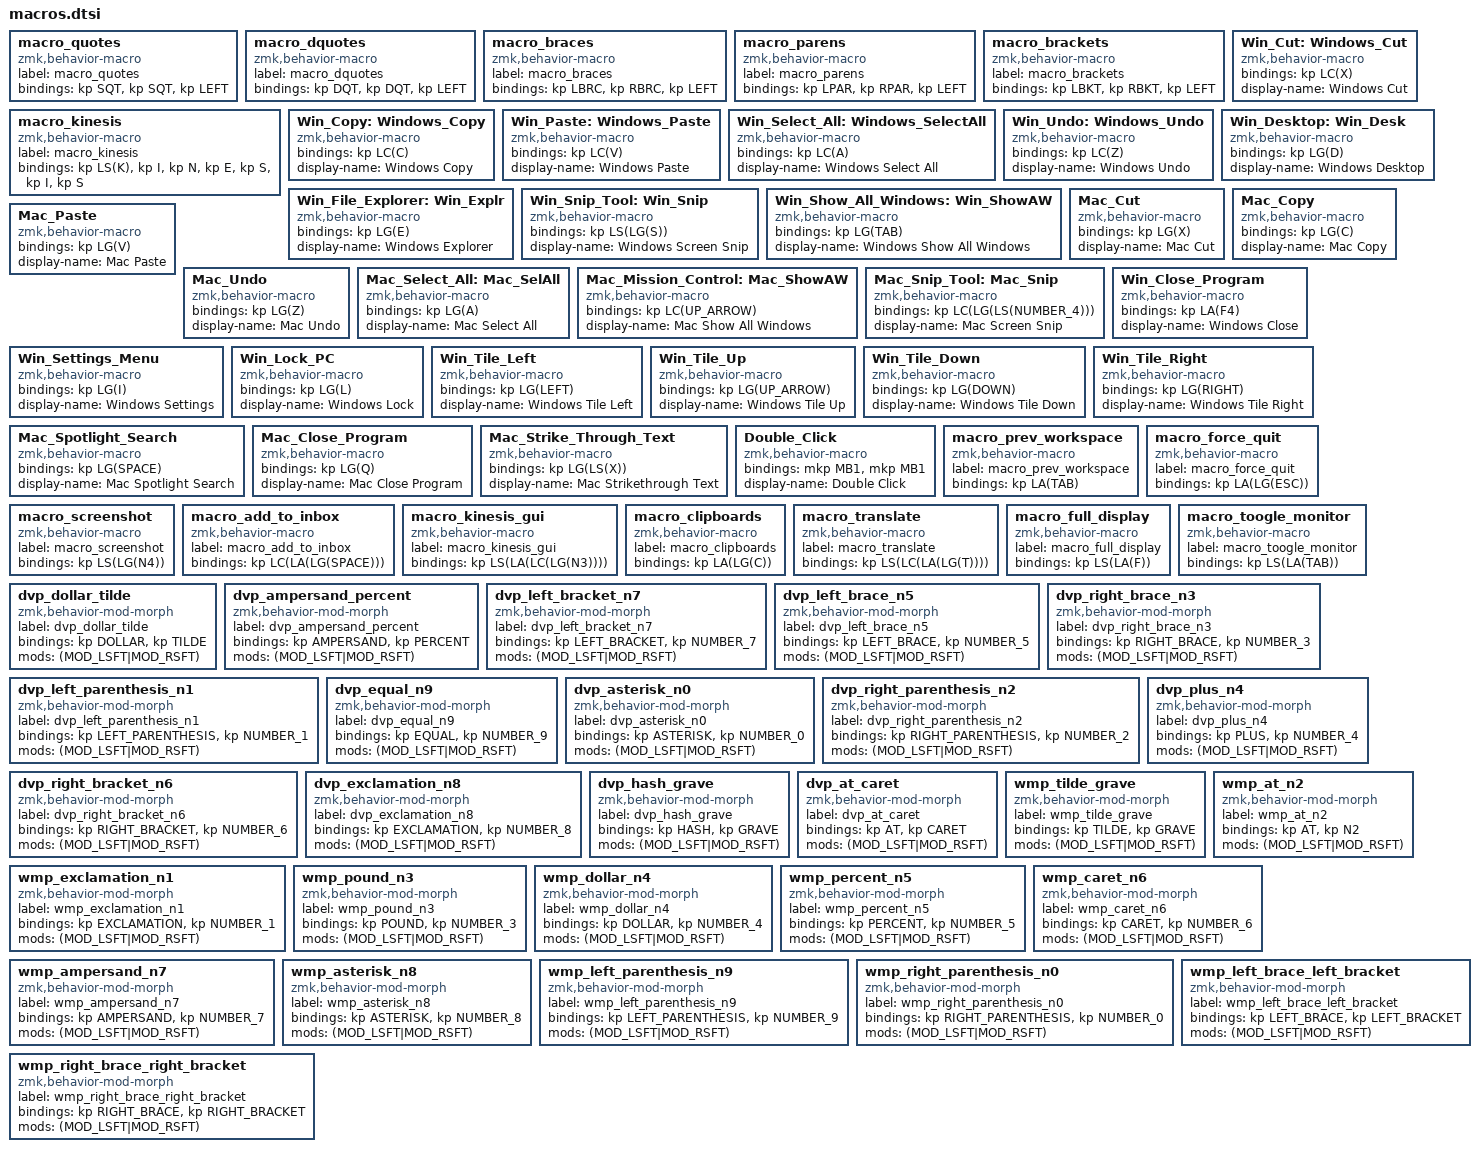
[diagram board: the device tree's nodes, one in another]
macro_quotes: macro_quotes {
    compatible = "zmk,behavior-macro";
    label = "macro_quotes";
    #binding-cells = <0>;
    bindings = <&kp SQT>, <&kp SQT>, <&kp LEFT>;
  };
  macro_dquotes: macro_dquotes {
    compatible = "zmk,behavior-macro";
    label = "macro_dquotes";
    #binding-cells = <0>;
    bindings = <&kp DQT>, <&kp DQT>, <&kp LEFT>;
  };
  macro_braces: macro_braces {
    compatible = "zmk,behavior-macro";
    label = "macro_braces";
    #binding-cells = <0>;
    bindings = <&kp LBRC>, <&kp RBRC>, <&kp LEFT>;
  };
  macro_parens: macro_parens {
    compatible = "zmk,behavior-macro";
    label = "macro_parens";
    #binding-cells = <0>;
    bindings = <&kp LPAR>, <&kp RPAR>, <&kp LEFT>;
  };
  macro_brackets: macro_brackets {
    compatible = "zmk,behavior-macro";
    label = "macro_brackets";
    #binding-cells = <0>;
    bindings = <&kp LBKT>, <&kp RBKT>, <&kp LEFT>;
  };
  macro_kinesis: macro_kinesis {
    compatible = "zmk,behavior-macro";
    label = "macro_kinesis";
    #binding-cells = <0>;
    bindings = <&kp LS(K)>, <&kp I>, <&kp N>, <&kp E>, <&kp S>, <&kp I>, <&kp S>;
  };
  Win_Cut: Windows_Cut {
    compatible = "zmk,behavior-macro";
    #binding-cells = <0>;
    bindings = <&kp LC(X)>;
    display-name = "Windows Cut";
  };

  Win_Copy: Windows_Copy {
    compatible = "zmk,behavior-macro";
    #binding-cells = <0>;
    bindings = <&kp LC(C)>;
    display-name = "Windows Copy";
  };

  Win_Paste: Windows_Paste {
    compatible = "zmk,behavior-macro";
    #binding-cells = <0>;
    bindings = <&kp LC(V)>;
    display-name = "Windows Paste";
  };

  Win_Select_All: Windows_SelectAll {
      compatible = "zmk,behavior-macro";
      #binding-cells = <0>;
      bindings = <&kp LC(A)>;
      display-name = "Windows Select All";
  };

  Win_Undo: Windows_Undo {
    compatible = "zmk,behavior-macro";
    #binding-cells = <0>;
    bindings = <&kp LC(Z)>;
    display-name = "Windows Undo";
  };

  Win_Desktop: Win_Desk {
    compatible = "zmk,behavior-macro";
    #binding-cells = <0>;
    bindings = <&kp LG(D)>;
    display-name = "Windows Desktop";
  };

  Win_File_Explorer: Win_Explr {
    compatible = "zmk,behavior-macro";
    #binding-cells = <0>;
    bindings = <&kp LG(E)>;
    display-name = "Windows Explorer";
  };

  Win_Snip_Tool: Win_Snip {
    compatible = "zmk,behavior-macro";
    #binding-cells = <0>;
    bindings = <&kp LS(LG(S))>;
    display-name = "Windows Screen Snip";
  };

  Win_Show_All_Windows: Win_ShowAW {
    compatible = "zmk,behavior-macro";
    #binding-cells = <0>;
    bindings = <&kp LG(TAB)>;
    display-name = "Windows Show All Windows";
  };

  Mac_Cut: Mac_Cut {
    compatible = "zmk,behavior-macro";
    #binding-cells = <0>;
    bindings = <&kp LG(X)>;
    display-name = "Mac Cut";
  };

  Mac_Copy: Mac_Copy {
    compatible = "zmk,behavior-macro";
    #binding-cells = <0>;
    bindings = <&kp LG(C)>;
    display-name = "Mac Copy";
  };

  Mac_Paste: Mac_Paste {
    compatible = "zmk,behavior-macro";
    #binding-cells = <0>;
    bindings = <&kp LG(V)>;
    display-name = "Mac Paste";
  };

  Mac_Undo: Mac_Undo {
    compatible = "zmk,behavior-macro";
    #binding-cells = <0>;
    bindings = <&kp LG(Z)>;
    display-name = "Mac Undo";
  };

  Mac_Select_All: Mac_SelAll {
    compatible = "zmk,behavior-macro";
    #binding-cells = <0>;
    bindings = <&kp LG(A)>;
    display-name = "Mac Select All";
  };

  Mac_Mission_Control: Mac_ShowAW {
    compatible = "zmk,behavior-macro";
    #binding-cells = <0>;
    bindings = <&kp LC(UP_ARROW)>;
    display-name = "Mac Show All Windows";
  };

  Mac_Snip_Tool: Mac_Snip {
    compatible = "zmk,behavior-macro";
    #binding-cells = <0>;
    bindings = <&kp LC(LG(LS(NUMBER_4)))>;
    display-name = "Mac Screen Snip";
  };

  Win_Close_Program: Win_Close_Program {
    compatible = "zmk,behavior-macro";
    #binding-cells = <0>;
    bindings = <&kp LA(F4)>;
    display-name = "Windows Close";
  };

  Win_Settings_Menu: Win_Settings_Menu {
    compatible = "zmk,behavior-macro";
    #binding-cells = <0>;
    bindings = <&kp LG(I)>;
    display-name = "Windows Settings";
  };

  Win_Lock_PC: Win_Lock_PC {
    compatible = "zmk,behavior-macro";
    #binding-cells = <0>;
    bindings = <&kp LG(L)>;
    display-name = "Windows Lock";
  };

  Win_Tile_Left: Win_Tile_Left {
    compatible = "zmk,behavior-macro";
    #binding-cells = <0>;
    bindings = <&kp LG(LEFT)>;
    display-name = "Windows Tile Left";
  };

  Win_Tile_Up: Win_Tile_Up {
    compatible = "zmk,behavior-macro";
    #binding-cells = <0>;
    bindings = <&kp LG(UP_ARROW)>;
    display-name = "Windows Tile Up";
  };

  Win_Tile_Down: Win_Tile_Down {
    compatible = "zmk,behavior-macro";
    #binding-cells = <0>;
    bindings = <&kp LG(DOWN)>;
    display-name = "Windows Tile Down";
  };

  Win_Tile_Right: Win_Tile_Right {
    compatible = "zmk,behavior-macro";
    #binding-cells = <0>;
    bindings = <&kp LG(RIGHT)>;
    display-name = "Windows Tile Right";
  };

  Mac_Spotlight_Search: Mac_Spotlight_Search {
    compatible = "zmk,behavior-macro";
    #binding-cells = <0>;
    bindings = <&kp LG(SPACE)>;
    display-name = "Mac Spotlight Search";
  };

  Mac_Close_Program: Mac_Close_Program {
    compatible = "zmk,behavior-macro";
    #binding-cells = <0>;
    bindings = <&kp LG(Q)>;
    display-name = "Mac Close Program";
  };

  Mac_Strike_Through_Text: Mac_Strike_Through_Text {
    compatible = "zmk,behavior-macro";
    #binding-cells = <0>;
    bindings = <&kp LG(LS(X))>;
    display-name = "Mac Strikethrough Text";
  };

  Double_Click: Double_Click {
    compatible = "zmk,behavior-macro";
    #binding-cells = <0>;
    bindings = <&mkp MB1 &mkp MB1>;
    display-name = "Double Click";
  };
macro_prev_workspace: macro_prev_workspace{
  compatible = "zmk,behavior-macro";
  label = "macro_prev_workspace";
  #binding-cells = <0>;
  bindings = <&kp LA(TAB)>;
};
macro_force_quit: macro_force_quit{
  compatible = "zmk,behavior-macro";
  label = "macro_force_quit";
  #binding-cells = <0>;
  bindings = <&kp LA(LG(ESC))>;
};
macro_screenshot: macro_screenshot{
  compatible = "zmk,behavior-macro";
  label = "macro_screenshot";
  #binding-cells = <0>;
  bindings = <&kp LS(LG(N4))>;
};
macro_add_to_inbox: macro_add_to_inbox{
  compatible = "zmk,behavior-macro";
  label = "macro_add_to_inbox";
  #binding-cells = <0>;
  bindings = <&kp LC(LA(LG(SPACE)))>;
};
macro_kinesis_gui: macro_kinesis_gui{
  compatible = "zmk,behavior-macro";
  label = "macro_kinesis_gui";
  #binding-cells = <0>;
  bindings = <&kp LS(LA(LC(LG(N3))))>;
};
macro_clipboards: macro_clipboards{
  compatible = "zmk,behavior-macro";
  label = "macro_clipboards";
  #binding-cells = <0>;
  bindings = <&kp LA(LG(C))>;
};
macro_translate: macro_translate{
  compatible = "zmk,behavior-macro";
  label = "macro_translate";
  #binding-cells = <0>;
  bindings = <&kp LS(LC(LA(LG(T))))>;
};
macro_full_display: macro_full_display{
  compatible = "zmk,behavior-macro";
  label = "macro_full_display";
  #binding-cells = <0>;
  bindings = <&kp LS(LA(F))>;
};
macro_toogle_monitor: macro_toogle_monitor{
  compatible = "zmk,behavior-macro";
  label = "macro_toogle_monitor";
  #binding-cells = <0>;
  bindings = <&kp LS(LA(TAB))>;
};

dvp_dollar_tilde: dvp_dollar_tilde {
    compatible = "zmk,behavior-mod-morph";
    label = "dvp_dollar_tilde";
    #binding-cells = <0>;
    bindings = <&kp DOLLAR>, <&kp TILDE>;
    mods = <(MOD_LSFT|MOD_RSFT)>;
};
dvp_ampersand_percent: dvp_ampersand_percent {
    compatible = "zmk,behavior-mod-morph";
    label = "dvp_ampersand_percent";
    #binding-cells = <0>;
    bindings = <&kp AMPERSAND>, <&kp PERCENT>;
    mods = <(MOD_LSFT|MOD_RSFT)>;
};
dvp_left_bracket_n7: dvp_left_bracket_n7 {
    compatible = "zmk,behavior-mod-morph";
    label = "dvp_left_bracket_n7";
    #binding-cells = <0>;
    bindings = <&kp LEFT_BRACKET>, <&kp NUMBER_7>;
    mods = <(MOD_LSFT|MOD_RSFT)>;
};
dvp_left_brace_n5: dvp_left_brace_n5 {
    compatible = "zmk,behavior-mod-morph";
    label = "dvp_left_brace_n5";
    #binding-cells = <0>;
    bindings = <&kp LEFT_BRACE>, <&kp NUMBER_5>;
    mods = <(MOD_LSFT|MOD_RSFT)>;
};
dvp_right_brace_n3: dvp_right_brace_n3 {
    compatible = "zmk,behavior-mod-morph";
    label = "dvp_right_brace_n3";
    #binding-cells = <0>;
    bindings = <&kp RIGHT_BRACE>, <&kp NUMBER_3>;
    mods = <(MOD_LSFT|MOD_RSFT)>;
};
dvp_left_parenthesis_n1: dvp_left_parenthesis_n1 {
    compatible = "zmk,behavior-mod-morph";
    label = "dvp_left_parenthesis_n1";
    #binding-cells = <0>;
    bindings = <&kp LEFT_PARENTHESIS>, <&kp NUMBER_1>;
    mods = <(MOD_LSFT|MOD_RSFT)>;
};
dvp_equal_n9: dvp_equal_n9 {
    compatible = "zmk,behavior-mod-morph";
    label = "dvp_equal_n9";
    #binding-cells = <0>;
    bindings = <&kp EQUAL>, <&kp NUMBER_9>;
    mods = <(MOD_LSFT|MOD_RSFT)>;
};
dvp_asterisk_n0: dvp_asterisk_n0 {
    compatible = "zmk,behavior-mod-morph";
    label = "dvp_asterisk_n0";
    #binding-cells = <0>;
    bindings = <&kp ASTERISK>, <&kp NUMBER_0>;
    mods = <(MOD_LSFT|MOD_RSFT)>;
};
dvp_right_parenthesis_n2: dvp_right_parenthesis_n2 {
    compatible = "zmk,behavior-mod-morph";
    label = "dvp_right_parenthesis_n2";
    #binding-cells = <0>;
    bindings = <&kp RIGHT_PARENTHESIS>, <&kp NUMBER_2>;
    mods = <(MOD_LSFT|MOD_RSFT)>;
};
dvp_plus_n4: dvp_plus_n4 {
    compatible = "zmk,behavior-mod-morph";
    label = "dvp_plus_n4";
    #binding-cells = <0>;
    bindings = <&kp PLUS>, <&kp NUMBER_4>;
    mods = <(MOD_LSFT|MOD_RSFT)>;
};
dvp_right_bracket_n6: dvp_right_bracket_n6 {
    compatible = "zmk,behavior-mod-morph";
    label = "dvp_right_bracket_n6";
    #binding-cells = <0>;
    bindings = <&kp RIGHT_BRACKET>, <&kp NUMBER_6>;
    mods = <(MOD_LSFT|MOD_RSFT)>;
};
dvp_exclamation_n8: dvp_exclamation_n8 {
    compatible = "zmk,behavior-mod-morph";
    label = "dvp_exclamation_n8";
    #binding-cells = <0>;
    bindings = <&kp EXCLAMATION>, <&kp NUMBER_8>;
    mods = <(MOD_LSFT|MOD_RSFT)>;
};
dvp_hash_grave: dvp_hash_grave {
    compatible = "zmk,behavior-mod-morph";
    label = "dvp_hash_grave";
    #binding-cells = <0>;
    bindings = <&kp HASH>, <&kp GRAVE>;
    mods = <(MOD_LSFT|MOD_RSFT)>;
};
dvp_at_caret: dvp_at_caret {
    compatible = "zmk,behavior-mod-morph";
    label = "dvp_at_caret";
    #binding-cells = <0>;
    bindings = <&kp AT>, <&kp CARET>;
    mods = <(MOD_LSFT|MOD_RSFT)>;
};
wmp_tilde_grave: wmp_tilde_grave {
    compatible = "zmk,behavior-mod-morph";
    label = "wmp_tilde_grave";
    #binding-cells = <0>;
    bindings = <&kp TILDE>, <&kp GRAVE>;
    mods = <(MOD_LSFT|MOD_RSFT)>;
};
wmp_exclamation_n1: wmp_exclamation_n1 {
    compatible = "zmk,behavior-mod-morph";
    label = "wmp_exclamation_n1";
    #binding-cells = <0>;
    bindings = <&kp EXCLAMATION>, <&kp NUMBER_1>;
    mods = <(MOD_LSFT|MOD_RSFT)>;
};
wmp_at_n2: wmp_at_n2 {
    compatible = "zmk,behavior-mod-morph";
    label = "wmp_at_n2";
    #binding-cells = <0>;
    bindings = <&kp AT>, <&kp N2>;
    mods = <(MOD_LSFT|MOD_RSFT)>;
};
wmp_pound_n3: wmp_pound_n3 {
    compatible = "zmk,behavior-mod-morph";
    label = "wmp_pound_n3";
    #binding-cells = <0>;
    bindings = <&kp POUND>, <&kp NUMBER_3>;
    mods = <(MOD_LSFT|MOD_RSFT)>;
};
wmp_dollar_n4: wmp_dollar_n4 {
    compatible = "zmk,behavior-mod-morph";
    label = "wmp_dollar_n4";
    #binding-cells = <0>;
    bindings = <&kp DOLLAR>, <&kp NUMBER_4>;
    mods = <(MOD_LSFT|MOD_RSFT)>;
};
wmp_percent_n5: wmp_percent_n5 {
    compatible = "zmk,behavior-mod-morph";
    label = "wmp_percent_n5";
    #binding-cells = <0>;
    bindings = <&kp PERCENT>, <&kp NUMBER_5>;
    mods = <(MOD_LSFT|MOD_RSFT)>;
};
wmp_caret_n6: wmp_caret_n6 {
    compatible = "zmk,behavior-mod-morph";
    label = "wmp_caret_n6";
    #binding-cells = <0>;
    bindings = <&kp CARET>, <&kp NUMBER_6>;
    mods = <(MOD_LSFT|MOD_RSFT)>;
};
wmp_ampersand_n7: wmp_ampersand_n7 {
    compatible = "zmk,behavior-mod-morph";
    label = "wmp_ampersand_n7";
    #binding-cells = <0>;
    bindings = <&kp AMPERSAND>, <&kp NUMBER_7>;
    mods = <(MOD_LSFT|MOD_RSFT)>;
};
wmp_asterisk_n8: wmp_asterisk_n8 {
    compatible = "zmk,behavior-mod-morph";
    label = "wmp_asterisk_n8";
    #binding-cells = <0>;
    bindings = <&kp ASTERISK>, <&kp NUMBER_8>;
    mods = <(MOD_LSFT|MOD_RSFT)>;
};
wmp_left_parenthesis_n9: wmp_left_parenthesis_n9 {
    compatible = "zmk,behavior-mod-morph";
    label = "wmp_left_parenthesis_n9";
    #binding-cells = <0>;
    bindings = <&kp LEFT_PARENTHESIS>, <&kp NUMBER_9>;
    mods = <(MOD_LSFT|MOD_RSFT)>;
};
wmp_right_parenthesis_n0: wmp_right_parenthesis_n0 {
    compatible = "zmk,behavior-mod-morph";
    label = "wmp_right_parenthesis_n0";
    #binding-cells = <0>;
    bindings = <&kp RIGHT_PARENTHESIS>, <&kp NUMBER_0>;
    mods = <(MOD_LSFT|MOD_RSFT)>;
};
wmp_left_brace_left_bracket: wmp_left_brace_left_bracket {
    compatible = "zmk,behavior-mod-morph";
    label = "wmp_left_brace_left_bracket";
    #binding-cells = <0>;
    bindings = <&kp LEFT_BRACE>, <&kp LEFT_BRACKET>;
    mods = <(MOD_LSFT|MOD_RSFT)>;
};
wmp_right_brace_right_bracket: wmp_right_brace_right_bracket {
    compatible = "zmk,behavior-mod-morph";
    label = "wmp_right_brace_right_bracket";
    #binding-cells = <0>;
    bindings = <&kp RIGHT_BRACE>, <&kp RIGHT_BRACKET>;
    mods = <(MOD_LSFT|MOD_RSFT)>;
};
